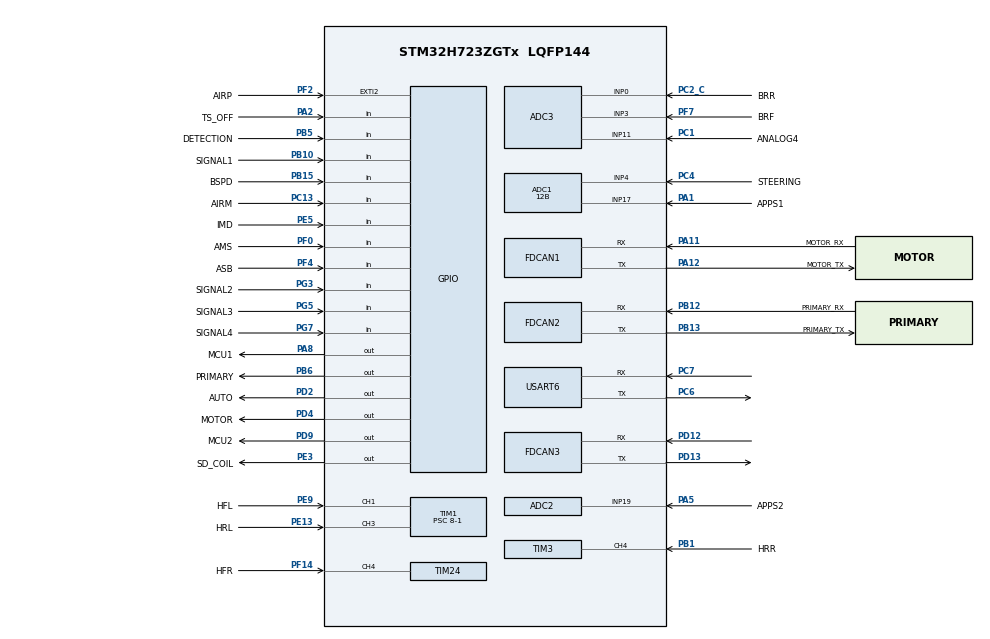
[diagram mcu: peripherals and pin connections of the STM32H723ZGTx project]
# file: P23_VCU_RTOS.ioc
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ADC1.Channel-0\#ChannelRegularConversion=ADC_CHANNEL_17
ADC1.Channel-1\#ChannelRegularConversion=ADC_CHANNEL_4
ADC1.ClockPrescaler=ADC_CLOCK_SYNC_PCLK_DIV4
ADC1.ClockPrescalerADC3=ADC_CLOCK_SYNC_PCLK_DIV4
ADC1.ContinuousConvMode=ENABLE
ADC1.ConversionDataManagement=ADC_CONVERSIONDATA_DMA_CIRCULAR
ADC1.EOCSelection=ADC_EOC_SINGLE_CONV
ADC1.NbrOfConversion=2
ADC1.NbrOfConversionFlag=1
ADC1.OffsetNumber-0\#ChannelRegularConversion=ADC_OFFSET_NONE
ADC1.OffsetNumber-1\#ChannelRegularConversion=ADC_OFFSET_NONE
ADC1.OffsetSignedSaturation-0\#ChannelRegularConversion=DISABLE
ADC1.Overrun=ADC_OVR_DATA_OVERWRITTEN
ADC1.Rank-0\#ChannelRegularConversion=1
ADC1.Rank-1\#ChannelRegularConversion=2
ADC1.Resolution=ADC_RESOLUTION_12B
ADC1.SamplingTime-0\#ChannelRegularConversion=ADC_SAMPLETIME_810CYCLES_5
ADC1.SamplingTime-1\#ChannelRegularConversion=ADC_SAMPLETIME_810CYCLES_5
ADC1.master=1
ADC2.Channel-0\#ChannelRegularConversion=ADC_CHANNEL_19
ADC2.ClockPrescaler=ADC_CLOCK_SYNC_PCLK_DIV4
ADC2.ClockPrescalerADC3=ADC_CLOCK_SYNC_PCLK_DIV4
ADC2.ContinuousConvMode=ENABLE
ADC2.ConversionDataManagement=ADC_CONVERSIONDATA_DMA_CIRCULAR
ADC2.EOCSelection=ADC_EOC_SINGLE_CONV
ADC2.NbrOfConversionFlag=1
ADC2.OffsetNumber-0\#ChannelRegularConversion=ADC_OFFSET_NONE
ADC2.OffsetSignedSaturation-0\#ChannelRegularConversion=DISABLE
ADC2.Overrun=ADC_OVR_DATA_OVERWRITTEN
ADC2.Rank-0\#ChannelRegularConversion=1
ADC2.Resolution=ADC_RESOLUTION_12B
ADC2.SamplingTime-0\#ChannelRegularConversion=ADC_SAMPLETIME_810CYCLES_5
ADC3.Channel-0\#ChannelRegularConversion=ADC_CHANNEL_0
ADC3.Channel-1\#ChannelRegularConversion=ADC_CHANNEL_3
ADC3.ClockPrescaler=ADC_CLOCK_SYNC_PCLK_DIV4
ADC3.ClockPrescalerADC3=ADC_CLOCK_SYNC_PCLK_DIV4
ADC3.ContinuousConvMode=ENABLE
ADC3.ConversionDataManagement=ADC_CONVERSIONDATA_DMA_CIRCULAR
ADC3.DMAContinuousRequests=ENABLE
ADC3.EOCSelection=ADC_EOC_SINGLE_CONV
ADC3.NbrOfConversion=2
ADC3.NbrOfConversionFlag=1
ADC3.OffsetNumber-0\#ChannelRegularConversion=ADC_OFFSET_NONE
ADC3.OffsetNumber-1\#ChannelRegularConversion=ADC_OFFSET_NONE
ADC3.OffsetSign-0\#ChannelRegularConversion=ADC3_OFFSET_SIGN_NEGATIVE
ADC3.OffsetSign-1\#ChannelRegularConversion=ADC3_OFFSET_SIGN_NEGATIVE
ADC3.Overrun=ADC_OVR_DATA_OVERWRITTEN
ADC3.Rank-0\#ChannelRegularConversion=1
ADC3.Rank-1\#ChannelRegularConversion=2
ADC3.SamplingTime-0\#ChannelRegularConversion=ADC3_SAMPLETIME_640CYCLES_5
ADC3.SamplingTime-1\#ChannelRegularConversion=ADC3_SAMPLETIME_640CYCLES_5
Dma.ADC1.2.Direction=DMA_PERIPH_TO_MEMORY
Dma.ADC1.2.EventEnable=DISABLE
Dma.ADC1.2.FIFOMode=DMA_FIFOMODE_DISABLE
Dma.ADC1.2.Instance=DMA1_Stream1
Dma.ADC1.2.MemDataAlignment=DMA_MDATAALIGN_HALFWORD
Dma.ADC1.2.MemInc=DMA_MINC_ENABLE
Dma.ADC1.2.Mode=DMA_CIRCULAR
Dma.ADC1.2.PeriphDataAlignment=DMA_PDATAALIGN_HALFWORD
Dma.ADC1.2.PeriphInc=DMA_PINC_DISABLE
Dma.ADC1.2.Polarity=HAL_DMAMUX_REQ_GEN_RISING
Dma.ADC1.2.Priority=DMA_PRIORITY_LOW
Dma.ADC1.2.RequestNumber=1
Dma.ADC1.2.SignalID=NONE
Dma.ADC1.2.SyncEnable=DISABLE
Dma.ADC1.2.SyncPolarity=HAL_DMAMUX_SYNC_NO_EVENT
Dma.ADC1.2.SyncRequestNumber=1
Dma.ADC1.2.SyncSignalID=NONE
Dma.ADC2.1.Direction=DMA_PERIPH_TO_MEMORY
Dma.ADC2.1.EventEnable=DISABLE
Dma.ADC2.1.FIFOMode=DMA_FIFOMODE_DISABLE
Dma.ADC2.1.Instance=DMA1_Stream2
Dma.ADC2.1.MemDataAlignment=DMA_MDATAALIGN_HALFWORD
Dma.ADC2.1.MemInc=DMA_MINC_ENABLE
Dma.ADC2.1.Mode=DMA_CIRCULAR
Dma.ADC2.1.PeriphDataAlignment=DMA_PDATAALIGN_HALFWORD
Dma.ADC2.1.PeriphInc=DMA_PINC_DISABLE
Dma.ADC2.1.Polarity=HAL_DMAMUX_REQ_GEN_RISING
Dma.ADC2.1.Priority=DMA_PRIORITY_LOW
Dma.ADC2.1.RequestNumber=1
Dma.ADC2.1.SignalID=NONE
Dma.ADC2.1.SyncEnable=DISABLE
Dma.ADC2.1.SyncPolarity=HAL_DMAMUX_SYNC_NO_EVENT
Dma.ADC2.1.SyncRequestNumber=1
Dma.ADC2.1.SyncSignalID=NONE
Dma.ADC3.0.Direction=DMA_PERIPH_TO_MEMORY
Dma.ADC3.0.EventEnable=DISABLE
Dma.ADC3.0.FIFOMode=DMA_FIFOMODE_DISABLE
Dma.ADC3.0.Instance=DMA2_Stream0
Dma.ADC3.0.MemDataAlignment=DMA_MDATAALIGN_HALFWORD
Dma.ADC3.0.MemInc=DMA_MINC_ENABLE
Dma.ADC3.0.Mode=DMA_CIRCULAR
Dma.ADC3.0.PeriphDataAlignment=DMA_PDATAALIGN_HALFWORD
Dma.ADC3.0.PeriphInc=DMA_PINC_DISABLE
Dma.ADC3.0.Polarity=HAL_DMAMUX_REQ_GEN_RISING
Dma.ADC3.0.Priority=DMA_PRIORITY_LOW
Dma.ADC3.0.RequestNumber=1
Dma.ADC3.0.SignalID=NONE
Dma.ADC3.0.SyncEnable=DISABLE
Dma.ADC3.0.SyncPolarity=HAL_DMAMUX_SYNC_NO_EVENT
Dma.ADC3.0.SyncRequestNumber=1
Dma.ADC3.0.SyncSignalID=NONE
Dma.Request0=ADC3
Dma.Request1=ADC2
Dma.Request2=ADC1
FDCAN1.AutoRetransmission=ENABLE
FDCAN1.CalculateBaudRateNominal=1000000
FDCAN1.CalculateTimeBitNominal=1000
FDCAN1.CalculateTimeQuantumNominal=12.5
FDCAN1.ClockCalibrationCCU=DISABLE
FDCAN1.DataPrescaler=1
FDCAN1.DataSyncJumpWidth=4
FDCAN1.DataTimeSeg1=5
FDCAN1.DataTimeSeg2=4
FDCAN1.FrameFormat=FDCAN_FRAME_CLASSIC
FDCAN1.Mode=FDCAN_MODE_NORMAL
FDCAN1.NominalPrescaler=1
FDCAN1.NominalSyncJumpWidth=16
FDCAN1.NominalTimeSeg1=63
FDCAN1.NominalTimeSeg2=16
FDCAN1.ProtocolException=ENABLE
FDCAN1.RxFifo0ElmtsNbr=1
FDCAN1.StdFiltersNbr=1
FDCAN1.TransmitPause=DISABLE
FDCAN1.TxFifoQueueElmtsNbr=1
FDCAN2.AutoRetransmission=ENABLE
FDCAN2.CalculateBaudRateNominal=1000000
FDCAN2.CalculateTimeBitNominal=1000
FDCAN2.CalculateTimeQuantumNominal=12.5
FDCAN2.ClockCalibrationCCU=DISABLE
FDCAN2.DataSyncJumpWidth=4
FDCAN2.DataTimeSeg1=5
FDCAN2.DataTimeSeg2=4
FDCAN2.FrameFormat=FDCAN_FRAME_CLASSIC
FDCAN2.MessageRAMOffset=9
FDCAN2.Mode=FDCAN_MODE_NORMAL
FDCAN2.NominalPrescaler=1
FDCAN2.NominalSyncJumpWidth=16
FDCAN2.NominalTimeSeg1=63
FDCAN2.NominalTimeSeg2=16
FDCAN2.ProtocolException=ENABLE
FDCAN2.RxFifo1ElmtsNbr=1
FDCAN2.StdFiltersNbr=1
FDCAN2.TransmitPause=DISABLE
FDCAN2.TxFifoQueueElmtsNbr=1
FDCAN3.AutoRetransmission=ENABLE
FDCAN3.CalculateBaudRateNominal=1000000
FDCAN3.CalculateTimeBitNominal=1000
FDCAN3.CalculateTimeQuantumNominal=12.5
FDCAN3.ClockCalibrationCCU=DISABLE
FDCAN3.DataSyncJumpWidth=4
FDCAN3.DataTimeSeg1=5
FDCAN3.DataTimeSeg2=4
FDCAN3.FrameFormat=FDCAN_FRAME_CLASSIC
FDCAN3.MessageRAMOffset=18
FDCAN3.Mode=FDCAN_MODE_NORMAL
FDCAN3.NominalPrescaler=1
FDCAN3.NominalSyncJumpWidth=16
FDCAN3.NominalTimeSeg1=63
FDCAN3.NominalTimeSeg2=16
FDCAN3.ProtocolException=ENABLE
FDCAN3.RxFifo0ElmtsNbr=1
FDCAN3.StdFiltersNbr=1
FDCAN3.TransmitPause=DISABLE
FDCAN3.TxFifoQueueElmtsNbr=1
FREERTOS.Tasks01=defaultTask,24,128,StartDefaultTask,Default,NULL,Dynamic,NULL,NULL
FREERTOS.configGENERATE_RUN_TIME_STATS=1
FREERTOS.configUSE_STATS_FORMATTING_FUNCTIONS=1
Mcu.Family=STM32H7
Mcu.Name=STM32H723ZGTx
Mcu.Package=LQFP144
NVIC.DMA1_Stream1_IRQn=true\:5\:0\:false\:false\:true\:true\:false\:true\:true
NVIC.DMA1_Stream2_IRQn=true\:5\:0\:false\:false\:true\:true\:false\:true\:true
NVIC.DMA2_Stream0_IRQn=true\:5\:0\:false\:false\:true\:false\:false\:true\:true
NVIC.FDCAN1_IT0_IRQn=true\:5\:0\:false\:false\:true\:true\:true\:true\:true
NVIC.FDCAN2_IT1_IRQn=true\:5\:0\:false\:false\:true\:true\:true\:true\:true
NVIC.FDCAN3_IT0_IRQn=true\:5\:0\:false\:false\:true\:true\:true\:true\:true
NVIC.PriorityGroup=NVIC_PRIORITYGROUP_4
NVIC.TIM1_UP_IRQn=true\:5\:0\:false\:false\:true\:true\:true\:true\:true
NVIC.TIM24_IRQn=true\:5\:0\:false\:false\:true\:true\:true\:true\:true
NVIC.TIM3_IRQn=true\:5\:0\:false\:false\:true\:true\:true\:true\:true
NVIC.TIM7_IRQn=true\:15\:0\:false\:false\:true\:false\:false\:true\:true
NVIC.TimeBase=TIM7_IRQn
NVIC.TimeBaseIP=TIM7
PA1.GPIO_Label=APPS1
PA1.Mode=IN17-Single-Ended
PA1.Signal=ADC1_INP17
PA11.GPIO_Label=MOTOR_RX
PA11.Mode=FDCAN_Activate
PA11.Signal=FDCAN1_RX
PA12.GPIO_Label=MOTOR_TX
PA12.Mode=FDCAN_Activate
PA12.Signal=FDCAN1_TX
PA13(JTMS/SWDIO).GPIO_Label=SWDIO
PA13(JTMS/SWDIO).Mode=Serial_Wire
PA13(JTMS/SWDIO).Signal=DEBUG_JTMS-SWDIO
PA14(JTCK/SWCLK).GPIO_Label=SWCLK
PA14(JTCK/SWCLK).Mode=Serial_Wire
PA14(JTCK/SWCLK).Signal=DEBUG_JTCK-SWCLK
PA2.GPIO_Label=TS_OFF
PA2.Signal=GPIO_Input
PA5.GPIO_Label=APPS2
PA5.Signal=ADCx_INP19
PA8.GPIO_Label=MCU1
PA8.Signal=GPIO_Output
PB1.GPIO_Label=HRR
PB1.Signal=S_TIM3_CH4
PB10.GPIO_Label=SIGNAL1
PB10.Signal=GPIO_Input
PB12.GPIO_Label=PRIMARY_RX
PB12.Mode=FDCAN_Activate
PB12.Signal=FDCAN2_RX
PB13.GPIO_Label=PRIMARY_TX
PB13.Mode=FDCAN_Activate
PB13.Signal=FDCAN2_TX
PB15.GPIO_Label=BSPD
PB15.Signal=GPIO_Input
PB5.GPIO_Label=DETECTION
PB5.Signal=GPIO_Input
PB6.GPIO_Label=PRIMARY
PB6.Signal=GPIO_Output
PC1.GPIO_Label=ANALOG4
PC1.Signal=ADCx_INP11
PC13.GPIO_Label=AIRM
PC13.Signal=GPIO_Input
PC2_C.GPIO_Label=BRR
PC2_C.Mode=IN0-Single-Ended
PC2_C.Signal=ADC3_INP0
PC4.GPIO_Label=STEERING
PC4.Signal=ADCx_INP4
PC6.Mode=Asynchronous
PC6.Signal=USART6_TX
PC7.Mode=Asynchronous
PC7.Signal=USART6_RX
PD12.GPIO_Mode=GPIO_MODE_AF_PP
PD12.GPIO_PuPd=GPIO_NOPULL
PD12.GPIO_Speed=GPIO_SPEED_FREQ_LOW
PD12.Mode=FDCAN_Activate
PD12.Signal=FDCAN3_RX
PD13.GPIO_Mode=GPIO_MODE_AF_PP
PD13.GPIO_PuPd=GPIO_NOPULL
PD13.GPIO_Speed=GPIO_SPEED_FREQ_LOW
PD13.Mode=FDCAN_Activate
PD13.Signal=FDCAN3_TX
PD2.GPIO_Label=AUTO
PD2.Signal=GPIO_Output
PD4.GPIO_Label=MOTOR
PD4.Signal=GPIO_Output
PD9.GPIO_Label=MCU2
PD9.Signal=GPIO_Output
PE13.GPIO_Label=HRL
PE13.Signal=S_TIM1_CH3
PE3.GPIO_Label=SD_COIL
PE3.Signal=GPIO_Output
PE5.GPIO_Label=IMD
PE5.Signal=GPIO_Input
PE9.GPIO_Label=HFL
PE9.Signal=S_TIM1_CH1
PF0.GPIO_Label=AMS
PF0.Signal=GPIO_Input
PF14.GPIO_Label=HFR
PF14.Signal=S_TIM24_CH4
PF2.GPIO_Label=AIRP
PF2.Signal=GPXTI2
PF4.GPIO_Label=ASB
PF4.Signal=GPIO_Input
PF7.GPIO_Label=BRF
PF7.Mode=IN3-Single-Ended
PF7.Signal=ADC3_INP3
PG3.GPIO_Label=SIGNAL2
PG3.Signal=GPIO_Input
PG5.GPIO_Label=SIGNAL3
PG5.Signal=GPIO_Input
PG7.GPIO_Label=SIGNAL4
PG7.Signal=GPIO_Input
PH0-OSC_IN.Mode=HSE-External-Oscillator
PH0-OSC_IN.Signal=RCC_OSC_IN
PH1-OSC_OUT.Mode=HSE-External-Oscillator
PH1-OSC_OUT.Signal=RCC_OSC_OUT
ProjectManager.HeapSize=0x200
ProjectManager.StackSize=0x400
ProjectManager.TargetToolchain=STM32CubeIDE
RCC.ADCFreq_Value=160000000
RCC.APB1Freq_Value=137500000
RCC.APB2Freq_Value=137500000
RCC.APB3Freq_Value=137500000
RCC.APB4Freq_Value=137500000
RCC.CortexFreq_Value=550000000
RCC.D1PPRE=RCC_APB3_DIV2
RCC.D2PPRE1=RCC_APB1_DIV2
RCC.D2PPRE2=RCC_APB2_DIV2
RCC.D3PPRE=RCC_APB4_DIV2
RCC.DIVM1=1
RCC.DIVM2=1
RCC.DIVN1=68
RCC.DIVN2=40
RCC.DIVP1=1
RCC.DIVQ1=4
RCC.DIVQ2=4
RCC.FDCANCLockSelection=RCC_FDCANCLKSOURCE_PLL2
RCC.HCLKFreq_Value=275000000
RCC.HPRE=RCC_HCLK_DIV2
RCC.HSE_VALUE=8000000
RCC.PLL1_VCO_SEL-AdvancedSettings=RCC_PLL1VCOMEDIUM
RCC.PLLFRACN=6144
RCC.PLLSourceVirtual=RCC_PLLSOURCE_HSE
RCC.SYSCLKFreq_VALUE=550000000
RCC.SYSCLKSource=RCC_SYSCLKSOURCE_PLLCLK
RCC.USBFreq_Value=137500000
SH.ADCx_INP11.0=ADC3_INP11,IN11-Single-Ended
SH.ADCx_INP19.0=ADC2_INP19,IN19-Single-Ended
SH.ADCx_INP4.0=ADC1_INP4,IN4-Single-Ended
SH.S_TIM1_CH1.0=TIM1_CH1,Input_Capture1_from_TI1
SH.S_TIM1_CH3.0=TIM1_CH3,Input_Capture3_from_TI3
SH.S_TIM24_CH4.0=TIM24_CH4,Input_Capture4_from_TI4
SH.S_TIM3_CH4.0=TIM3_CH4,Input_Capture4_from_TI4
TIM1.AutoReloadPreload=TIM_AUTORELOAD_PRELOAD_ENABLE
TIM1.Channel-Input_Capture1_from_TI1=TIM_CHANNEL_1
TIM1.Channel-Input_Capture3_from_TI3=TIM_CHANNEL_3
TIM1.ICFilter_CH3=3
TIM1.Prescaler=8-1
TIM24.AutoReloadPreload=TIM_AUTORELOAD_PRELOAD_ENABLE
TIM24.Channel-Input_Capture4_from_TI4=TIM_CHANNEL_4
TIM24.ICFilter_CH4=3
TIM24.Period=65535
TIM24.Prescaler=8-1
TIM3.AutoReloadPreload=TIM_AUTORELOAD_PRELOAD_ENABLE
TIM3.Channel-Input_Capture4_from_TI4=TIM_CHANNEL_4
TIM3.ICFilter_CH4=3
TIM3.Prescaler=8-1
USART6.VirtualMode-Asynchronous=VM_ASYNC
VP_FREERTOS_VS_CMSIS_V2.Mode=CMSIS_V2
VP_SYS_VS_tim7.Mode=TIM7
VP_TIM1_VS_ClockSourceINT.Mode=Internal
VP_TIM3_VS_ClockSourceINT.Mode=Internal
board=custom

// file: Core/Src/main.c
/* USER CODE BEGIN Header */
/**
  ******************************************************************************
  * @file           : main.c
  * @brief          : Main program body
  ******************************************************************************
  * @attention
  *
  * Copyright (c) 2023 STMicroelectronics.
  * All rights reserved.
  *
  * This software is licensed under terms that can be found in the LICENSE file
  * in the root directory of this software component.
  * If no LICENSE file comes with this software, it is provided AS-IS.
  *
  ******************************************************************************
  */
/* USER CODE END Header */
#include "main.h"
#include "cmsis_os.h"
#include "adc.h"
#include "dma.h"
#include "fdcan.h"
#include "tim.h"
#include "usart.h"
#include "gpio.h"

/* USER CODE BEGIN Includes */
#include "shared_variables.h"
/* USER CODE END Includes */

void SystemClock_Config(void);
void PeriphCommonClock_Config(void);
void MX_FREERTOS_Init(void);

/* USER CODE BEGIN 0 */
//for debugging purposes: Window -> Show View -> FreeRTOS
extern TIM_HandleTypeDef htim7;
volatile unsigned long ulHighFrequencyTimerTicks;
 void configureTimerForRunTimeStats(void) {
   ulHighFrequencyTimerTicks = 0;
   HAL_TIM_Base_Start_IT(&htim7);
 }
 unsigned long getRunTimeCounterValue(void) {
   return ulHighFrequencyTimerTicks;
 }
/* USER CODE END 0 */

int main(void)
{

  /* MCU Configuration--------------------------------------------------------*/

  /* Reset of all peripherals, Initializes the Flash interface and the Systick. */
  HAL_Init();

  /* Configure the system clock */
  SystemClock_Config();

/* Configure the peripherals common clocks */
  PeriphCommonClock_Config();

  /* Initialize all configured peripherals */
  MX_GPIO_Init();
  MX_DMA_Init();
  MX_FDCAN2_Init();
  MX_ADC1_Init();
  MX_ADC2_Init();
  MX_ADC3_Init();
  MX_FDCAN1_Init();
  MX_FDCAN3_Init();
  MX_USART6_UART_Init();
  MX_TIM1_Init();
  MX_TIM3_Init();
  MX_TIM24_Init();
  /* USER CODE BEGIN 2 */
  HAL_Delay(1000);
  /* USER CODE END 2 */

  /* Init scheduler */
  osKernelInitialize();  /* Call init function for freertos objects (in freertos.c) */
  MX_FREERTOS_Init();

  /* Start scheduler */
  osKernelStart();

  /* We should never get here as control is now taken by the scheduler */
  /* Infinite loop */
  while (1)
  {

  }
}

void SystemClock_Config(void)
{
  RCC_OscInitTypeDef RCC_OscInitStruct = {0};
  RCC_ClkInitTypeDef RCC_ClkInitStruct = {0};

  /** Supply configuration update enable
  */
  HAL_PWREx_ConfigSupply(PWR_LDO_SUPPLY);

  /** Configure the main internal regulator output voltage
  */
  __HAL_PWR_VOLTAGESCALING_CONFIG(PWR_REGULATOR_VOLTAGE_SCALE0);

  while(!__HAL_PWR_GET_FLAG(PWR_FLAG_VOSRDY)) {}

  /** Initializes the RCC Oscillators according to the specified parameters
  * in the RCC_OscInitTypeDef structure.
  */
  RCC_OscInitStruct.OscillatorType = RCC_OSCILLATORTYPE_HSE;
  RCC_OscInitStruct.HSEState = RCC_HSE_ON;
  RCC_OscInitStruct.PLL.PLLState = RCC_PLL_ON;
  RCC_OscInitStruct.PLL.PLLSource = RCC_PLLSOURCE_HSE;
  RCC_OscInitStruct.PLL.PLLM = 1;
  RCC_OscInitStruct.PLL.PLLN = 68;
  RCC_OscInitStruct.PLL.PLLP = 1;
  RCC_OscInitStruct.PLL.PLLQ = 4;
  RCC_OscInitStruct.PLL.PLLR = 2;
  RCC_OscInitStruct.PLL.PLLRGE = RCC_PLL1VCIRANGE_3;
  RCC_OscInitStruct.PLL.PLLVCOSEL = RCC_PLL1VCOWIDE;
  RCC_OscInitStruct.PLL.PLLFRACN = 6144;
  if (HAL_RCC_OscConfig(&RCC_OscInitStruct) != HAL_OK)
  {
    Error_Handler();
  }

  /** Initializes the CPU, AHB and APB buses clocks
  */
  RCC_ClkInitStruct.ClockType = RCC_CLOCKTYPE_HCLK|RCC_CLOCKTYPE_SYSCLK
                              |RCC_CLOCKTYPE_PCLK1|RCC_CLOCKTYPE_PCLK2
                              |RCC_CLOCKTYPE_D3PCLK1|RCC_CLOCKTYPE_D1PCLK1;
  RCC_ClkInitStruct.SYSCLKSource = RCC_SYSCLKSOURCE_PLLCLK;
  RCC_ClkInitStruct.SYSCLKDivider = RCC_SYSCLK_DIV1;
  RCC_ClkInitStruct.AHBCLKDivider = RCC_HCLK_DIV2;
  RCC_ClkInitStruct.APB3CLKDivider = RCC_APB3_DIV2;
  RCC_ClkInitStruct.APB1CLKDivider = RCC_APB1_DIV2;
  RCC_ClkInitStruct.APB2CLKDivider = RCC_APB2_DIV2;
  RCC_ClkInitStruct.APB4CLKDivider = RCC_APB4_DIV2;

  if (HAL_RCC_ClockConfig(&RCC_ClkInitStruct, FLASH_LATENCY_3) != HAL_OK)
  {
    Error_Handler();
  }
}

void PeriphCommonClock_Config(void)
{
  RCC_PeriphCLKInitTypeDef PeriphClkInitStruct = {0};

  /** Initializes the peripherals clock
  */
  PeriphClkInitStruct.PeriphClockSelection = RCC_PERIPHCLK_FDCAN;
  PeriphClkInitStruct.PLL2.PLL2M = 1;
  PeriphClkInitStruct.PLL2.PLL2N = 40;
  PeriphClkInitStruct.PLL2.PLL2P = 2;
  PeriphClkInitStruct.PLL2.PLL2Q = 4;
  PeriphClkInitStruct.PLL2.PLL2R = 2;
  PeriphClkInitStruct.PLL2.PLL2RGE = RCC_PLL2VCIRANGE_3;
  PeriphClkInitStruct.PLL2.PLL2VCOSEL = RCC_PLL2VCOWIDE;
  PeriphClkInitStruct.PLL2.PLL2FRACN = 0;
  PeriphClkInitStruct.FdcanClockSelection = RCC_FDCANCLKSOURCE_PLL2;
  if (HAL_RCCEx_PeriphCLKConfig(&PeriphClkInitStruct) != HAL_OK)
  {
    Error_Handler();
  }
}

void HAL_TIM_PeriodElapsedCallback(TIM_HandleTypeDef *htim)
{
  if (htim->Instance == TIM7) {
    HAL_IncTick();
  }
  /* USER CODE BEGIN Callback 1 */
  if(htim->Instance == TIM1){
	  TIM1_OVC1++;
	  TIM1_OVC3++;
  }
  if(htim->Instance == TIM3){
	  TIM3_OVC++;
  }
  if(htim->Instance == TIM24){
	  TIM24_OVC++;
  }
  /* USER CODE END Callback 1 */
}

void Error_Handler(void)
{
  __disable_irq();
  while (1)
  {
  }
}
